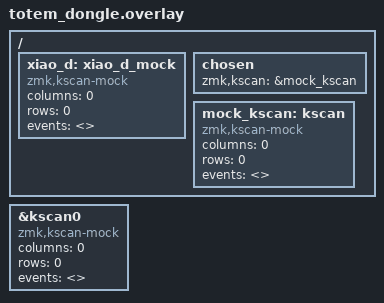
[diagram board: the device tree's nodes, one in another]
/*
 * Copyright (c) 2022 The ZMK Contributors
 *
 * SPDX-License-Identifier: MIT
 */

/* nice_nano에 존재하지 않는 xiao_d 핀 레이블을 컴파일러가 인식할 수 있도록 임시 가짜 매핑 */
/ {
    xiao_d: xiao_d_mock {
        compatible = "zmk,kscan-mock";
        columns = <0>;
        rows = <0>;
        events = <>;
    };
};

#include "totem.dtsi"

/* 키맵이나 원본 설정에서 연결된 기존 kscan0을 무력화하고 가짜 스캔 매트릭스 주입 */
/ {
    chosen {
        zmk,kscan = &mock_kscan;
    };

    mock_kscan: kscan {
        compatible = "zmk,kscan-mock";
        columns = <0>;
        rows = <0>;
        events = <>;
    };
};

/* 기존 kscan0 노드의 내용을 공백으로 오버라이드하여 핀 충돌 차단 */
&kscan0 {
    compatible = "zmk,kscan-mock";

    /delete-property/ col-gpios;
    /delete-property/ row-gpios;
    /delete-property/ diode-direction;

    columns = <0>;
    rows = <0>;
    events = <>;
};
